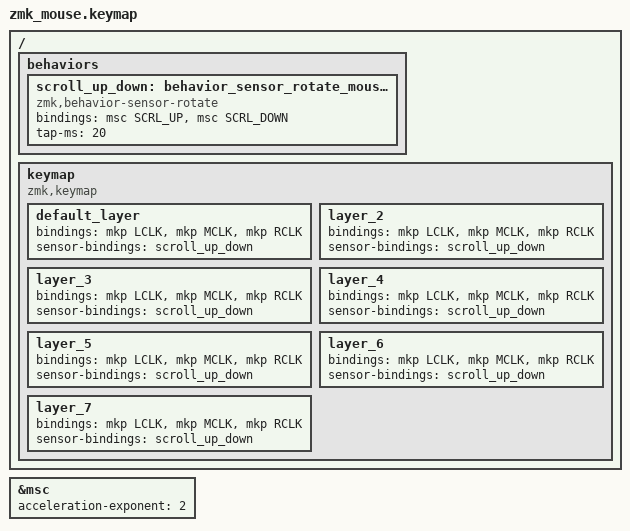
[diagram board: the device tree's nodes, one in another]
#include <behaviors.dtsi>
#include <dt-bindings/zmk/bt.h>
#include <dt-bindings/zmk/keys.h>
#include <dt-bindings/zmk/outputs.h>
#include <dt-bindings/zmk/pointing.h>


&msc {
    acceleration-exponent = <2>;
};

/ {

    behaviors {

        scroll_up_down: behavior_sensor_rotate_mouse_wheel_up_down {
            compatible = "zmk,behavior-sensor-rotate";
            #sensor-binding-cells = <0>;
            bindings = <&msc SCRL_UP>, <&msc SCRL_DOWN>;

            tap-ms = <20>;
        };
    };

    keymap {
        compatible = "zmk,keymap";

        default_layer {
            bindings = <
                &mkp LCLK    &mkp MCLK    &mkp RCLK
            >;

            sensor-bindings = <&scroll_up_down>;
        };
        layer_2 {
            bindings = <
                &mkp LCLK    &mkp MCLK    &mkp RCLK
            >;

            sensor-bindings = <&scroll_up_down>;
        };
        layer_3 {
            bindings = <
                &mkp LCLK    &mkp MCLK    &mkp RCLK
            >;

            sensor-bindings = <&scroll_up_down>;
        };
        layer_4 {
            bindings = <
                &mkp LCLK    &mkp MCLK    &mkp RCLK
            >;

            sensor-bindings = <&scroll_up_down>;
        };
        layer_5 {
            bindings = <
                &mkp LCLK    &mkp MCLK    &mkp RCLK
            >;

            sensor-bindings = <&scroll_up_down>;
        };
        layer_6 {
            bindings = <
                &mkp LCLK    &mkp MCLK    &mkp RCLK
            >;

            sensor-bindings = <&scroll_up_down>;
        };
        layer_7 {
            bindings = <
                &mkp LCLK    &mkp MCLK    &mkp RCLK
            >;

            sensor-bindings = <&scroll_up_down>;
        };
    };
};
